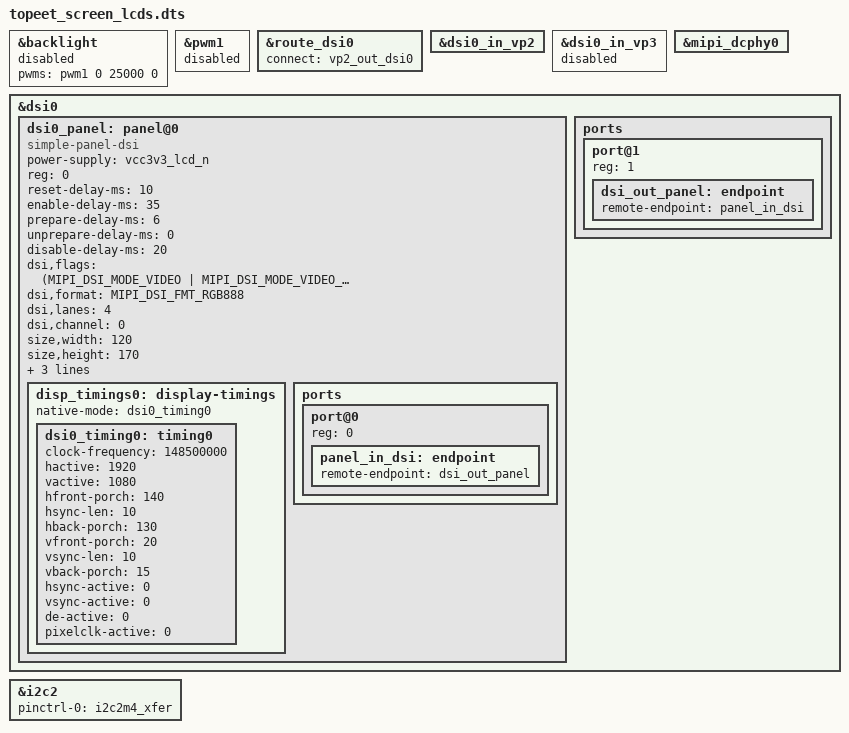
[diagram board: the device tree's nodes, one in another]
#define LCD_TYPE_MIPI0  //VP2
//#define LCD_TYPE_LVDS_10_1_1280x800_GT911  //VP2
//#define LCD_TYPE_LVDS_10_1_1280x800_GT9271 //VP2
//#define LCD_TYPE_LVDS_10_1_1024x600_GT911  //VP2
//#define LCD_TYPE_LVDS_7_0  //VP2
//#define LCD_TYPE_HDMI1  //VP1
//#define LCD_TYPE_HDMI0  //VP0
//#define LCD_TYPE_TYPEC_DP  //VP1
//#define LCD_TYPE_MIPI1    //VP3



&backlight {
        pwms = <&pwm1 0 25000 0>;
        status = "disable";
};

&pwm1 {
        status = "disable";
};

&route_dsi0 {
        status = "okay";
        connect = <&vp2_out_dsi0>;
};

/*
 * mipi_dcphy0 needs to be enabled
 * when dsi0 is enabled
 */
&dsi0_in_vp2 {
        status = "okay";
};

&dsi0_in_vp3 {
        status = "disabled";
};



&mipi_dcphy0 {
	status = "okay";
};

&dsi0 {
        status = "okay";
        //rockchip,lane-rate = <1000>;
        dsi0_panel: panel@0 {
                status = "okay";
                compatible = "simple-panel-dsi";
                power-supply = <&vcc3v3_lcd_n>;
                reg = <0>;
               // backlight = <&backlight>;
                reset-delay-ms = <10>;
                enable-delay-ms = <35>;
                prepare-delay-ms = <6>;
                unprepare-delay-ms = <0>;
                disable-delay-ms = <20>;
                dsi,flags = <(MIPI_DSI_MODE_VIDEO | MIPI_DSI_MODE_VIDEO_BURST |
                        MIPI_DSI_MODE_LPM | MIPI_DSI_MODE_EOT_PACKET)>;
                dsi,format = <MIPI_DSI_FMT_RGB888>;
                dsi,lanes  = <4>;
		dsi,channel = <0>;
		size,width = <120>;
	        size,height = <170>;
                
                panel-init-sequence = [
			29 00 02 27 AA
                        29 00 02 48 02
                        29 00 02 B6 20
                        29 00 02 01 80
                        29 00 02 02 38
                        29 00 02 03 47
                        29 00 02 04 8C
                        29 00 02 05 0A
                        29 00 02 06 82
                        29 00 02 07 00
                        29 00 02 08 14
                        29 00 02 09 0A
                        29 00 02 0A 0F
                        29 00 02 0B 02
                        29 00 02 0C 52
                        29 00 02 0D 01
                        29 00 02 0E 80
                        29 00 02 0F 20
                        29 00 02 10 20
                        29 00 02 11 03
                        29 00 02 12 1B
                        29 00 02 13 63
                        29 00 02 14 01
                        29 00 02 15 23
                        29 00 02 16 40
                        29 00 02 17 00
                        29 00 02 18 01
                        29 00 02 19 23
                        29 00 02 1A 40
                        29 00 02 1B 00
                        29 00 02 1E 46
                        29 00 02 51 30
                        29 00 02 1F 10
                        29 00 02 2A 01


			05 C8 01 11
			05 14 01 29
                ];
                panel-exit-sequence = [

                ];

                disp_timings0: display-timings {
                        native-mode = <&dsi0_timing0>;
                        dsi0_timing0: timing0 {
                                clock-frequency = <148500000>; //<60000000>;//71900000
                                hactive = <1920>; //<800>;
                                vactive = <1080>; //<1280>;
                                hfront-porch = <140>; //<80>;//20
                                hsync-len = <10>; //<20>;
                                hback-porch = <130>;//20
                                vfront-porch = <20>; //<20>;//10
                                vsync-len = <10>;
                                vback-porch = <15>; //<12>;//4
                                hsync-active = <0>;
                                vsync-active = <0>;
                                de-active = <0>;
                                pixelclk-active = <0>;
                        };
                };


#if 0
              panel-init-sequence = [
			23 00 02 27 AA
                        23 00 02 48 02
                        23 00 02 B6 20
                        23 00 02 01 80
                        23 00 02 02 38
                        23 00 02 03 47
                        23 00 02 04 06
                        23 00 02 05 04
                        23 00 02 06 50
                        23 00 02 07 00
                        23 00 02 08 06
                        23 00 02 09 04
                        23 00 02 0A 28
                        23 00 02 0B 02
                        23 00 02 0C 4C
                        23 00 02 0D 01
                        23 00 02 0E 80
                        23 00 02 0F 20
                        23 00 02 10 20
                        23 00 02 11 03
                        23 00 02 12 1B
                        23 00 02 13 63
                        23 00 02 14 01
                        23 00 02 15 23
                        23 00 02 16 40
                        23 00 02 17 00
                        23 00 02 18 01
                        23 00 02 19 23
                        23 00 02 1A 40
                        23 00 02 1B 00
                        23 00 02 1E 46
                        23 00 02 51 30
                        23 00 02 1F 10
                        23 00 02 2A 01

                ];
                panel-exit-sequence = [

                ];

                disp_timings0: display-timings {
                        native-mode = <&dsi0_timing0>;
                        dsi0_timing0: timing0 {
                                clock-frequency = <136300000>; //<60000000>;//71900000
                                hactive = <1920>; //<800>;
                                vactive = <1080>; //<1280>;
                                hfront-porch = <6>; //<80>;//20
                                hsync-len = <4>; //<20>;
                                hback-porch = <80>;//20
                                vfront-porch = <6>; //<20>;//10
                                vsync-len = <4>;
                                vback-porch = <40>; //<12>;//4
                                hsync-active = <0>;
                                vsync-active = <0>;
                                de-active = <0>;
                                pixelclk-active = <0>;
                        };
                };
#endif
                ports {
                        #address-cells = <1>;
                        #size-cells = <0>;

                        port@0 {
                                reg = <0>;
                                panel_in_dsi: endpoint {
                                        remote-endpoint = <&dsi_out_panel>;
                                };
                        };
                };
        };

        ports {
                #address-cells = <1>;
                #size-cells = <0>;

                port@1 {
                        reg = <1>;
                        dsi_out_panel: endpoint {
                                remote-endpoint = <&panel_in_dsi>;
                        };
                };
        };

};



&i2c2 {
	status = "okay";
	pinctrl-0 = <&i2c2m4_xfer>;
#if defined(LCD_TYPE_MIPI0) || defined(LCD_TYPE_LVDS_7_0)
/*
	ft5x06@38 {
		status = "okay";
		compatible = "edt,edt-ft5406";
		reg = <0x38>;
		touch-gpio = <&gpio3 RK_PC0 IRQ_TYPE_EDGE_RISING>;
		interrupt-parent = <&gpio3>;
		interrupts = <RK_PC0 IRQ_TYPE_LEVEL_LOW>;
		reset-gpios = <&gpio3 RK_PC1 GPIO_ACTIVE_LOW>;
		touchscreen-size-x = <800>;
		touchscreen-size-y = <1280>;
		

	};

       gm8775c@2c {
               compatible = "gm8775c,mipi_to_lvds";
               reg = <0x2c>;
               status = "okay";
                touch-gpio = <&gpio3 RK_PC0 IRQ_TYPE_EDGE_RISING>;
		interrupt-parent = <&gpio3>;
		interrupts = <RK_PC0 IRQ_TYPE_LEVEL_LOW>;
		reset-gpios = <&gpio3 RK_PC1 GPIO_ACTIVE_LOW>;
		touchscreen-size-x = <800>;
		touchscreen-size-y = <1280>;
       };
*/


#endif
};










